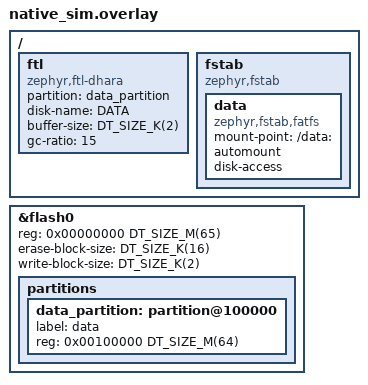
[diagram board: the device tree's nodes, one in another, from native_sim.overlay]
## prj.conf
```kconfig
CONFIG_LOG=y
CONFIG_LOG_DEFAULT_LEVEL=3
CONFIG_LOG_BUFFER_SIZE=8192

CONFIG_DISK_FTL_LOG_LEVEL_DBG=y
CONFIG_DISK_LOG_LEVEL_DBG=y
CONFIG_DMA_LOG_LEVEL_DBG=y
CONFIG_FLASH_LOG_LEVEL_DBG=y
CONFIG_FS_LOG_LEVEL_DBG=y
CONFIG_MEMC_LOG_LEVEL_DBG=y

CONFIG_SHELL=y

CONFIG_FLASH=y
CONFIG_FLASH_SHELL=y
CONFIG_FLASH_SHELL_TEST_COMMANDS=y
CONFIG_FLASH_SHELL_BUFFER_SIZE=0x20000
CONFIG_FLASH_MAP=y
CONFIG_FLASH_MAP_SHELL=y
CONFIG_FLASH_SIMULATOR_EX_OP=y

CONFIG_FILE_SYSTEM=y
CONFIG_FILE_SYSTEM_MKFS=y
CONFIG_FILE_SYSTEM_SHELL=y
CONFIG_FILE_SYSTEM_SHELL_TEST_COMMANDS=y
CONFIG_FAT_FILESYSTEM_ELM=y
CONFIG_FS_FATFS_FSTAB_AUTOMOUNT=y
CONFIG_FS_FATFS_LFN=y
CONFIG_FS_FATFS_LFN_MODE_STACK=y
CONFIG_FS_FATFS_MAX_SS=2048
CONFIG_FS_FATFS_MIN_SS=2048
CONFIG_FS_FATFS_REENTRANT=y

CONFIG_MAIN_STACK_SIZE=6144
CONFIG_SHELL_STACK_SIZE=4096
```

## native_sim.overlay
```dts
/ {
	ftl {
		compatible = "zephyr,ftl-dhara";
		partition = <&data_partition>;
		disk-name = "DATA";
		buffer-size = <DT_SIZE_K(2)>;
		gc-ratio = <15>;
	};

	fstab {
		compatible = "zephyr,fstab";

		data {
			compatible = "zephyr,fstab,fatfs";
			mount-point = "/data:";
			automount;
			disk-access;
		};
	};
};

/delete-node/ &storage_partition;
&flash0 {
	reg = <0x00000000 DT_SIZE_M(65)>;
	erase-block-size = <DT_SIZE_K(16)>;
	write-block-size = <DT_SIZE_K(2)>;

	partitions {
		data_partition: partition@100000 {
			label = "data";
			reg = <0x00100000 DT_SIZE_M(64)>;
		};
	};
};
```

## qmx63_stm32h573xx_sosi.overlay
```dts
/ {
	ftl {
		compatible = "zephyr,ftl-dhara";
		partition = <&data_partition>;
		disk-name = "DATA";
		buffer-size = <DT_SIZE_K(2)>;
		gc-ratio = <15>;
	};

	fstab {
		compatible = "zephyr,fstab";

		data {
			compatible = "zephyr,fstab,fatfs";
			mount-point = "/data:";
			automount;
			disk-access;
		};
	};
};
```

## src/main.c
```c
/*
 * Copyright (c) 2012-2014 Wind River Systems, Inc.
 *
 * SPDX-License-Identifier: Apache-2.0
 */

#include <stdio.h>

int main(void)
{
	printf("Hello World! %s\n", CONFIG_BOARD_TARGET);
	printf("NAND Flash Test Firmware\n");

	return 0;
}
```
